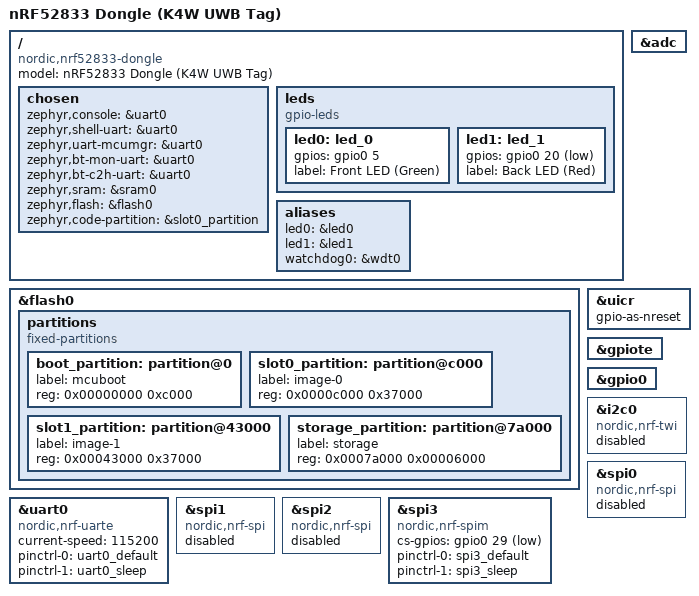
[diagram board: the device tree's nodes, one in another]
/*
 * Copyright (c) 2024 K4W UWB Tag
 * SPDX-License-Identifier: Apache-2.0
 */

/dts-v1/;
#include <nordic/nrf52833_qdaa.dtsi>
#include "nrf52833dongle_nrf52833-pinctrl.dtsi"

/ {
	model = "nRF52833 Dongle (K4W UWB Tag)";
	compatible = "nordic,nrf52833-dongle";

	chosen {
		zephyr,console = &uart0;
		zephyr,shell-uart = &uart0;
		zephyr,uart-mcumgr = &uart0;
		zephyr,bt-mon-uart = &uart0;
		zephyr,bt-c2h-uart = &uart0;
		zephyr,sram = &sram0;
		zephyr,flash = &flash0;
		zephyr,code-partition = &slot0_partition;
	};

	leds {
		compatible = "gpio-leds";
		led0: led_0 {
			gpios = <&gpio0 5 GPIO_ACTIVE_HIGH>;
			label = "Front LED (Green)";
		};
		led1: led_1 {
			gpios = <&gpio0 20 GPIO_ACTIVE_LOW>;
			label = "Back LED (Red)";
		};
	};

	aliases {
		led0 = &led0;
		led1 = &led1;
		watchdog0 = &wdt0;
	};
};

&flash0 {
	partitions {
		compatible = "fixed-partitions";
		#address-cells = <1>;
		#size-cells = <1>;

		boot_partition: partition@0 {
			label = "mcuboot";
			reg = <0x00000000 0xc000>;
		};
		slot0_partition: partition@c000 {
			label = "image-0";
			reg = <0x0000c000 0x37000>;
		};
		slot1_partition: partition@43000 {
			label = "image-1";
			reg = <0x00043000 0x37000>;
		};
		storage_partition: partition@7a000 {
			label = "storage";
			reg = <0x0007a000 0x00006000>;
		};
	};
};

&adc {
	status = "okay";
};

&uicr {
	gpio-as-nreset;
};

&gpiote {
	status = "okay";
};

&gpio0 {
	status = "okay";
};

&uart0 {
	compatible = "nordic,nrf-uarte";
	status = "okay";
	current-speed = <115200>;
	pinctrl-0 = <&uart0_default>;
	pinctrl-1 = <&uart0_sleep>;
	pinctrl-names = "default", "sleep";
};

&i2c0 {
	compatible = "nordic,nrf-twi";
	status = "disabled";
};

&spi0 {
	compatible = "nordic,nrf-spi";
	status = "disabled";
};

&spi1 {
	compatible = "nordic,nrf-spi";
	status = "disabled";
};

&spi2 {
	compatible = "nordic,nrf-spi";
	status = "disabled";
};

&spi3 {
	compatible = "nordic,nrf-spim";
	status = "okay";
	cs-gpios = <&gpio0 29 GPIO_ACTIVE_LOW>;
	pinctrl-0 = <&spi3_default>;
	pinctrl-1 = <&spi3_sleep>;
	pinctrl-names = "default", "sleep";
};
